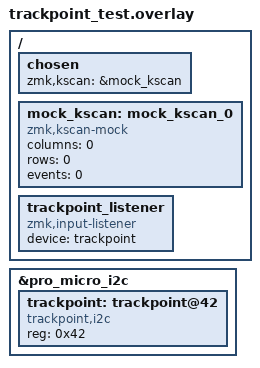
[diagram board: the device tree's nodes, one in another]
/ {
    chosen {
        zmk,kscan = &mock_kscan;
    };

    mock_kscan: mock_kscan_0 {
        compatible = "zmk,kscan-mock";
        columns = <0>;
        rows = <0>;
        events = <0>;
    };
};

&pro_micro_i2c {
    status = "okay";
    trackpoint: trackpoint@42 {
        compatible = "trackpoint,i2c";
        reg = <0x42>;
    };
};

/ {
    trackpoint_listener {
        compatible = "zmk,input-listener";
        device = <&trackpoint>;
    };
};
